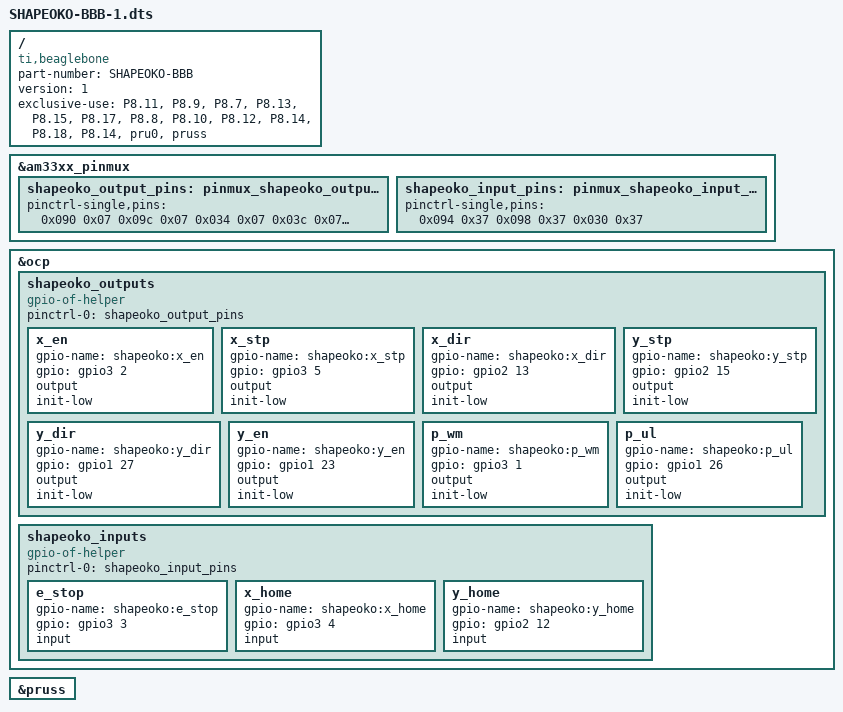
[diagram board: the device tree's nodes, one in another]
/dts-v1/;
/plugin/;

/ {
	compatible = "ti,beaglebone", "ti,beaglebone-black";

	/* identification */
	part-number = "SHAPEOKO-BBB";
	version = "1";

	exclusive-use =
		/* Steppers */
		"P8.11",  /* gpio 1.13 X-Dir     */
		"P8.9",   /* gpio 2.5  X-Step    */
		"P8.7",   /* gpio 2.2  X-Enable  */
		"P8.13",  /* gpio 0.23 Y-Dir     */
		"P8.15",  /* gpio 1.15 Y-Step    */
		"P8.17",  /* gpio 0.27 Y-Enable  */

		/* Home sw., E-Stop */
		"P8.8",   /* gpio 2.3  E-Stop    */
		"P8.10",  /* gpio 2.4  X-Home    */
		"P8.12",  /* gpio 1.12 Y-Home    */
		"P8.14",  /* gpio 0.26 Pulse     */

		/* Laser controll */
		"P8.18",  /* gpio 2.1  PWM       */
		"P8.14",  /* gpio 0.26 Pulse     */

		"pru0",
		"pruss";


	fragment@2 {
		target = <&am33xx_pinmux>;
		__overlay__ {

			shapeoko_output_pins: pinmux_shapeoko_output_pins {
				status = "okay";
				pinctrl-single,pins = <
					/* stepper outputs (MODE 7, NO receiver, NO pullups, Fast slew) */
					0x090 0x07  /* X-Enable */
					0x09c 0x07  /* X-Step   */
					0x034 0x07  /* X-Dir    */
					0x03c 0x07  /* Y-Step   */
					0x02c 0x07  /* Y-Dir    */
					0x024 0x07  /* Y-Enable */
					/* Laser PWM (Mode 7, NO receiver, NO pullups, Fast slew) */
					0x08c 0x07  /* PWM      */
					/* Laser PULSE out (MODE 7, NO receiver, NO pullups, Fast slwe) */
					0x028 0x07  /* PULSE    */
				>;
			};
		};
	};


	fragment@3 {
		target = <&ocp>;
		__overlay__ {

			shapeoko_outputs {
				compatible = "gpio-of-helper";
				status = "okay";
				pinctrl-names = "default";
				pinctrl-0 = <&shapeoko_output_pins>;

				x_en {
					gpio-name = "shapeoko:x_en";
					gpio = <&gpio3 2 0>;
					output;
					init-low;
				};
				x_stp {
					gpio-name = "shapeoko:x_stp";
					gpio = <&gpio3 5 0>;
					output;
					init-low;
				};
				x_dir {
					gpio-name = "shapeoko:x_dir";
					gpio = <&gpio2 13 0>;
					output;
					init-low;
				};
				y_stp {
					gpio-name = "shapeoko:y_stp";
					gpio = <&gpio2 15 0>;
					output;
					init-low;
				};
				y_dir {
					gpio-name = "shapeoko:y_dir";
					gpio = <&gpio1 27 0>;
					output;
					init-low;
				};
				y_en {
					gpio-name = "shapeoko:y_en";
					gpio = <&gpio1 23 0>;
					output;
					init-low;
				};
				p_wm {
					gpio-name = "shapeoko:p_wm";
					gpio = <&gpio3 1 0>;
					output;
					init-low;
				};
				p_ul {
					gpio-name = "shapeoko:p_ul";
					gpio = <&gpio1 26 0>;
					output;
					init-low;
				};
			};
		};
	};


	fragment@4 {
		target = <&am33xx_pinmux>;
		 __overlay__ {

			shapeoko_input_pins: pinmux_shapeoko_input_pins {
				status = "okay";
				pinctrl-single,pins = <
					/* Switch sensors (MODE 7, Receiver, Pullups, Fast slew) */
					0x094 0x37 /* E-Stop */
					0x098 0x37 /* X-Home */
					0x030 0x37 /* Y-Home */
				>;
			};
		};
	};


	fragment@5 {
		target = <&ocp>;
		__overlay__ {

			shapeoko_inputs {
				compatible = "gpio-of-helper";
				status = "okay";
				pinctrl-names = "default";
				pinctrl-0 = <&shapeoko_input_pins>;

				e_stop {
					gpio-name = "shapeoko:e_stop";
					gpio = <&gpio3 3 0>;
					input;
				};
				x_home {
					gpio-name = "shapeoko:x_home";
					gpio = <&gpio3 4 0>;
					input;
				};
				y_home {
					gpio-name = "shapeoko:y_home";
					gpio = <&gpio2 12 0>;
					input;
				};
			};
		};
	};


	fragment@6 {
		target = <&pruss>;
		__overlay__ {
			status = "okay";
			pinctrl-names = "default";
		};
	};
};
